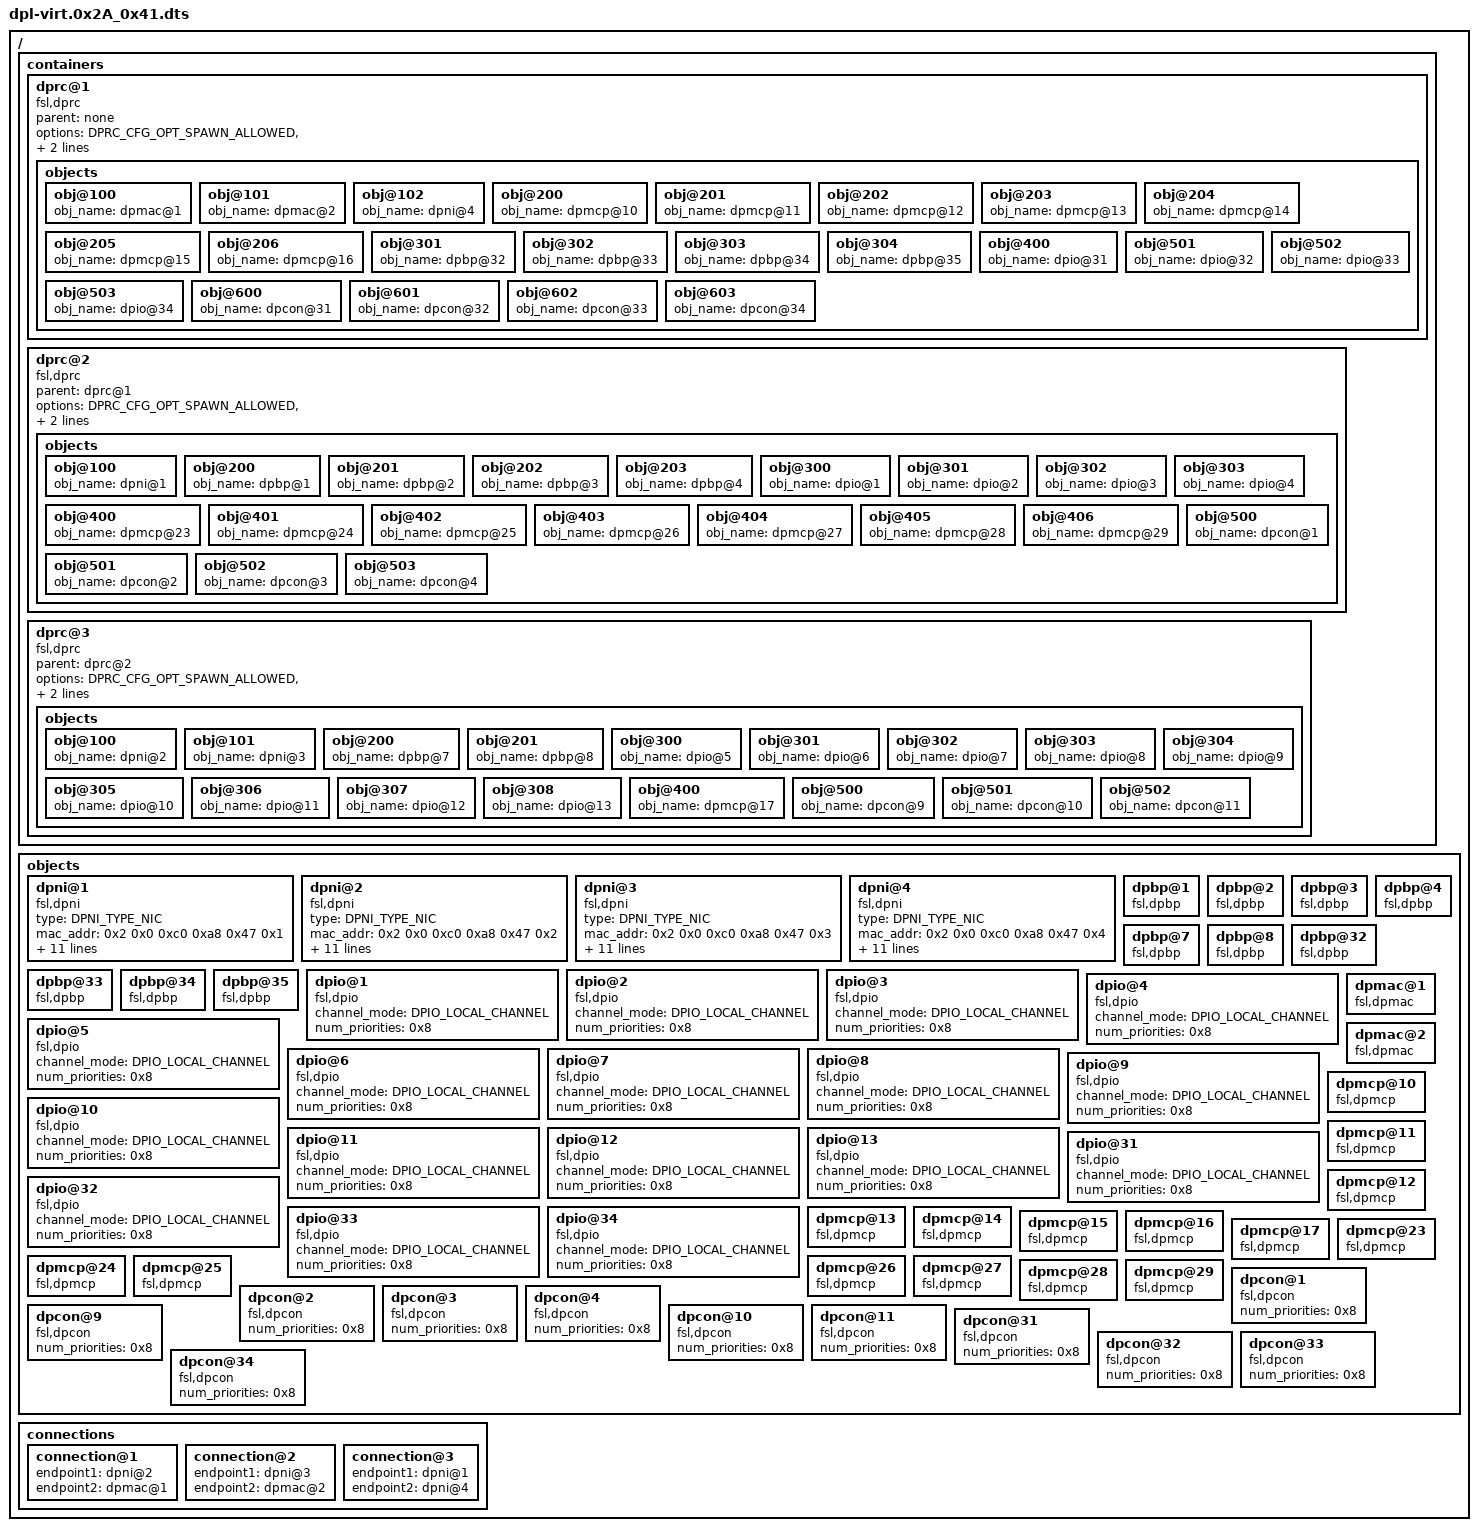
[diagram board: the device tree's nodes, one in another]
/dts-v1/;

/ {

	containers {

		dprc@1 {
			compatible = "fsl,dprc";
			parent = "none";
			options = "DPRC_CFG_OPT_SPAWN_ALLOWED", "DPRC_CFG_OPT_ALLOC_ALLOWED", "DPRC_CFG_OPT_IRQ_CFG_ALLOWED";

			objects {

				obj@100 {
					obj_name = "dpmac@1";
				};

				obj@101 {
					obj_name = "dpmac@2";
				};

				obj@102 {
					obj_name = "dpni@4";
				};

				obj@200 {
					obj_name = "dpmcp@10";
				};

				obj@201 {
					obj_name = "dpmcp@11";
				};

				obj@202 {
					obj_name = "dpmcp@12";
				};

				obj@203 {
					obj_name = "dpmcp@13";
				};

				obj@204 {
					obj_name = "dpmcp@14";
				};

				obj@205 {
					obj_name = "dpmcp@15";
				};

				obj@206 {
					obj_name = "dpmcp@16";
				};
				obj@301 {
					obj_name = "dpbp@32";
				};

				obj@302 {
					obj_name = "dpbp@33";
				};

				obj@303 {
					obj_name = "dpbp@34";
				};

				obj@304 {
					obj_name = "dpbp@35";
				};

				obj@400 {
					obj_name = "dpio@31";
				};

				obj@501 {
					obj_name = "dpio@32";
				};

				obj@502 {
					obj_name = "dpio@33";
				};

				obj@503 {
					obj_name = "dpio@34";
				};

				obj@600 {
					obj_name = "dpcon@31";
				};

				obj@601 {
					obj_name = "dpcon@32";
				};

				obj@602 {
					obj_name = "dpcon@33";
				};

				obj@603 {
					obj_name = "dpcon@34";
				};


			};
		};

		dprc@2 {
			compatible = "fsl,dprc";
			parent = "dprc@1";
			options = "DPRC_CFG_OPT_SPAWN_ALLOWED", "DPRC_CFG_OPT_ALLOC_ALLOWED", "DPRC_CFG_OPT_IRQ_CFG_ALLOWED";

			objects {

				obj@100 {
					obj_name = "dpni@1";
				};

				obj@200 {
					obj_name = "dpbp@1";
				};

				obj@201 {
					obj_name = "dpbp@2";
				};

				obj@202 {
					obj_name = "dpbp@3";
				};

				obj@203 {
					obj_name = "dpbp@4";
				};

				obj@300 {
					obj_name = "dpio@1";
				};

				obj@301 {
					obj_name = "dpio@2";
				};

				obj@302 {
					obj_name = "dpio@3";
				};

				obj@303 {
					obj_name = "dpio@4";
				};

				obj@400 {
					obj_name = "dpmcp@23";
				};

				obj@401 {
					obj_name = "dpmcp@24";
				};

				obj@402 {
					obj_name = "dpmcp@25";
				};

				obj@403 {
					obj_name = "dpmcp@26";
				};

				obj@404 {
					obj_name = "dpmcp@27";
				};

				obj@405 {
					obj_name = "dpmcp@28";
				};

				obj@406 {
					obj_name = "dpmcp@29";
				};

				obj@500 {
					obj_name = "dpcon@1";
				};

				obj@501 {
					obj_name = "dpcon@2";
				};

				obj@502 {
					obj_name = "dpcon@3";
				};

				obj@503 {
					obj_name = "dpcon@4";
				};
			};
		};

		dprc@3 {
			compatible = "fsl,dprc";
			parent = "dprc@2";
			options = "DPRC_CFG_OPT_SPAWN_ALLOWED", "DPRC_CFG_OPT_ALLOC_ALLOWED", "DPRC_CFG_OPT_IRQ_CFG_ALLOWED";

			objects {

				obj@100 {
					obj_name = "dpni@2";
				};

				obj@101 {
					obj_name = "dpni@3";
				};

				obj@200 {
					obj_name = "dpbp@7";
				};

				obj@201 {
					obj_name = "dpbp@8";
				};

				obj@300 {
					obj_name = "dpio@5";
				};

				obj@301 {
					obj_name = "dpio@6";
				};

				obj@302 {
					obj_name = "dpio@7";
				};

				obj@303 {
					obj_name = "dpio@8";
				};

				obj@304 {
					obj_name = "dpio@9";
				};

				obj@305 {
					obj_name = "dpio@10";
				};

				obj@306 {
					obj_name = "dpio@11";
				};

				obj@307 {
					obj_name = "dpio@12";
				};

				obj@308 {
					obj_name = "dpio@13";
				};

				obj@400 {
					obj_name = "dpmcp@17";
				};

				obj@500 {
					obj_name = "dpcon@9";
				};

				obj@501 {
					obj_name = "dpcon@10";
				};

				obj@502 {
					obj_name = "dpcon@11";
				};
			};
		};
	};

	objects {

		dpni@1 {
			compatible = "fsl,dpni";
			type = "DPNI_TYPE_NIC";
			mac_addr = <0x2 0x0 0xc0 0xa8 0x47 0x1>;
			max_senders = <0x4>;
			options = "DPNI_OPT_MULTICAST_FILTER", "DPNI_OPT_UNICAST_FILTER", "DPNI_OPT_DIST_HASH";
			max_tcs = <0x1>;
			max_dist_per_tc = <0x3 0x0 0x0>;
			max_unicast_filters = <0x0>;
			max_multicast_filters = <0x0>;
			max_vlan_filters = <0x0>;
			max_qos_entries = <0x0>;
			max_qos_key_size = <0x0>;
			max_dist_key_size = <0x4>;
		};

		dpni@2 {
			compatible = "fsl,dpni";
			type = "DPNI_TYPE_NIC";
			mac_addr = <0x2 0x0 0xc0 0xa8 0x47 0x2>;
			max_senders = <0x4>;
			options = "DPNI_OPT_MULTICAST_FILTER", "DPNI_OPT_UNICAST_FILTER", "DPNI_OPT_DIST_HASH";
			max_tcs = <0x1>;
			max_dist_per_tc = <0x8 0x0 0x0>;
			max_unicast_filters = <0x0>;
			max_multicast_filters = <0x0>;
			max_vlan_filters = <0x0>;
			max_qos_entries = <0x0>;
			max_qos_key_size = <0x0>;
			max_dist_key_size = <0x4>;
		};

		dpni@3 {
			compatible = "fsl,dpni";
			type = "DPNI_TYPE_NIC";
			mac_addr = <0x2 0x0 0xc0 0xa8 0x47 0x3>;
			max_senders = <0x4>;
			options = "DPNI_OPT_MULTICAST_FILTER", "DPNI_OPT_UNICAST_FILTER", "DPNI_OPT_DIST_HASH";
			max_tcs = <0x1>;
			max_dist_per_tc = <0x8 0x0 0x0>;
			max_unicast_filters = <0x0>;
			max_multicast_filters = <0x0>;
			max_vlan_filters = <0x0>;
			max_qos_entries = <0x0>;
			max_qos_key_size = <0x0>;
			max_dist_key_size = <0x4>;
		};

		dpni@4 {
			compatible = "fsl,dpni";
			type = "DPNI_TYPE_NIC";
			mac_addr = <0x2 0x0 0xc0 0xa8 0x47 0x4>;
			max_senders = <0x4>;
			options = "DPNI_OPT_MULTICAST_FILTER", "DPNI_OPT_UNICAST_FILTER", "DPNI_OPT_DIST_HASH";
			max_tcs = <0x1>;
			max_dist_per_tc = <0x8 0x0 0x0>;
			max_unicast_filters = <0x0>;
			max_multicast_filters = <0x0>;
			max_vlan_filters = <0x0>;
			max_qos_entries = <0x0>;
			max_qos_key_size = <0x0>;
			max_dist_key_size = <0x4>;
		};

		dpbp@1 {
			compatible = "fsl,dpbp";
		};

		dpbp@2 {
			compatible = "fsl,dpbp";
		};

		dpbp@3 {
			compatible = "fsl,dpbp";
		};

		dpbp@4 {
			compatible = "fsl,dpbp";
		};

		dpbp@7 {
			compatible = "fsl,dpbp";
		};

		dpbp@8 {
			compatible = "fsl,dpbp";
		};

		dpbp@32 {
			compatible = "fsl,dpbp";
		};

		dpbp@33 {
			compatible = "fsl,dpbp";
		};

		dpbp@34 {
			compatible = "fsl,dpbp";
		};

		dpbp@35 {
			compatible = "fsl,dpbp";
		};

		dpio@1 {
			compatible = "fsl,dpio";
			channel_mode = "DPIO_LOCAL_CHANNEL";
			num_priorities = <0x8>;
		};

		dpio@2 {
			compatible = "fsl,dpio";
			channel_mode = "DPIO_LOCAL_CHANNEL";
			num_priorities = <0x8>;
		};

		dpio@3 {
			compatible = "fsl,dpio";
			channel_mode = "DPIO_LOCAL_CHANNEL";
			num_priorities = <0x8>;
		};

		dpio@4 {
			compatible = "fsl,dpio";
			channel_mode = "DPIO_LOCAL_CHANNEL";
			num_priorities = <0x8>;
		};

		dpio@5 {
			compatible = "fsl,dpio";
			channel_mode = "DPIO_LOCAL_CHANNEL";
			num_priorities = <0x8>;
		};

		dpio@6 {
			compatible = "fsl,dpio";
			channel_mode = "DPIO_LOCAL_CHANNEL";
			num_priorities = <0x8>;
		};

		dpio@7 {
			compatible = "fsl,dpio";
			channel_mode = "DPIO_LOCAL_CHANNEL";
			num_priorities = <0x8>;
		};

		dpio@8 {
			compatible = "fsl,dpio";
			channel_mode = "DPIO_LOCAL_CHANNEL";
			num_priorities = <0x8>;
		};

		dpio@9 {
			compatible = "fsl,dpio";
			channel_mode = "DPIO_LOCAL_CHANNEL";
			num_priorities = <0x8>;
		};

		dpio@10 {
			compatible = "fsl,dpio";
			channel_mode = "DPIO_LOCAL_CHANNEL";
			num_priorities = <0x8>;
		};

		dpio@11 {
			compatible = "fsl,dpio";
			channel_mode = "DPIO_LOCAL_CHANNEL";
			num_priorities = <0x8>;
		};

		dpio@12 {
			compatible = "fsl,dpio";
			channel_mode = "DPIO_LOCAL_CHANNEL";
			num_priorities = <0x8>;
		};

		dpio@13 {
			compatible = "fsl,dpio";
			channel_mode = "DPIO_LOCAL_CHANNEL";
			num_priorities = <0x8>;
		};

		dpio@31 {
			compatible = "fsl,dpio";
			channel_mode = "DPIO_LOCAL_CHANNEL";
			num_priorities = <0x8>;
		};

		dpio@32 {
			compatible = "fsl,dpio";
			channel_mode = "DPIO_LOCAL_CHANNEL";
			num_priorities = <0x8>;
		};

		dpio@33 {
			compatible = "fsl,dpio";
			channel_mode = "DPIO_LOCAL_CHANNEL";
			num_priorities = <0x8>;
		};

		dpio@34 {
			compatible = "fsl,dpio";
			channel_mode = "DPIO_LOCAL_CHANNEL";
			num_priorities = <0x8>;
		};

		dpmac@1 {
			compatible = "fsl,dpmac";
		};

		dpmac@2 {
			compatible = "fsl,dpmac";
		};

		dpmcp@10 {
			compatible = "fsl,dpmcp";
		};

		dpmcp@11 {
			compatible = "fsl,dpmcp";
		};

		dpmcp@12 {
			compatible = "fsl,dpmcp";
		};

		dpmcp@13 {
			compatible = "fsl,dpmcp";
		};

		dpmcp@14 {
			compatible = "fsl,dpmcp";
		};

		dpmcp@15 {
			compatible = "fsl,dpmcp";
		};

		dpmcp@16 {
			compatible = "fsl,dpmcp";
		};

		dpmcp@17 {
			compatible = "fsl,dpmcp";
		};

		dpmcp@23 {
			compatible = "fsl,dpmcp";
		};

		dpmcp@24 {
			compatible = "fsl,dpmcp";
		};

		dpmcp@25 {
			compatible = "fsl,dpmcp";
		};

		dpmcp@26 {
			compatible = "fsl,dpmcp";
		};

		dpmcp@27 {
			compatible = "fsl,dpmcp";
		};

		dpmcp@28 {
			compatible = "fsl,dpmcp";
		};

		dpmcp@29 {
			compatible = "fsl,dpmcp";
		};

		dpcon@1 {
			compatible = "fsl,dpcon";
			num_priorities = <0x8>;
		};

		dpcon@2 {
			compatible = "fsl,dpcon";
			num_priorities = <0x8>;
		};

		dpcon@3 {
			compatible = "fsl,dpcon";
			num_priorities = <0x8>;
		};

		dpcon@4 {
			compatible = "fsl,dpcon";
			num_priorities = <0x8>;
		};

		dpcon@9 {
			compatible = "fsl,dpcon";
			num_priorities = <0x8>;
		};

		dpcon@10 {
			compatible = "fsl,dpcon";
			num_priorities = <0x8>;
		};

		dpcon@11 {
			compatible = "fsl,dpcon";
			num_priorities = <0x8>;
		};

		dpcon@31 {
			compatible = "fsl,dpcon";
			num_priorities = <0x8>;
		};

		dpcon@32 {
			compatible = "fsl,dpcon";
			num_priorities = <0x8>;
		};

		dpcon@33 {
			compatible = "fsl,dpcon";
			num_priorities = <0x8>;
		};

		dpcon@34 {
			compatible = "fsl,dpcon";
			num_priorities = <0x8>;
		};

	};

	connections {

		connection@1 {
			endpoint1 = "dpni@2";
			endpoint2 = "dpmac@1";
		};

		connection@2 {
			endpoint1 = "dpni@3";
			endpoint2 = "dpmac@2";
		};

		connection@3 {
			endpoint1 = "dpni@1";
			endpoint2 = "dpni@4";
		};

	};
};
